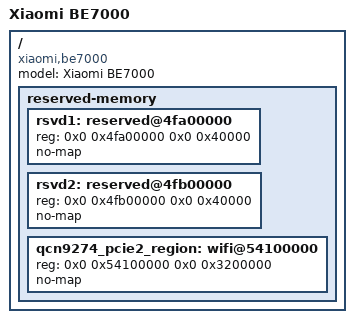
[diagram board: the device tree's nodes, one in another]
// SPDX-License-Identifier: (GPL-2.0+ OR BSD-3-Clause)

/dts-v1/;

#include "ipq9574-be7000-common.dtsi"

/ {
	model = "Xiaomi BE7000";
	compatible = "xiaomi,be7000", "qcom,ipq9574";

	reserved-memory {
		rsvd1: reserved@4fa00000 {
			reg = <0x0 0x4fa00000 0x0 0x40000>;
			no-map;
		};

		rsvd2: reserved@4fb00000 {
			reg = <0x0 0x4fb00000 0x0 0x40000>;
			no-map;
		};

		qcn9274_pcie2_region: wifi@54100000 {
			reg = <0x0 0x54100000 0x0 0x3200000>;
			no-map;
		};
	};
};
